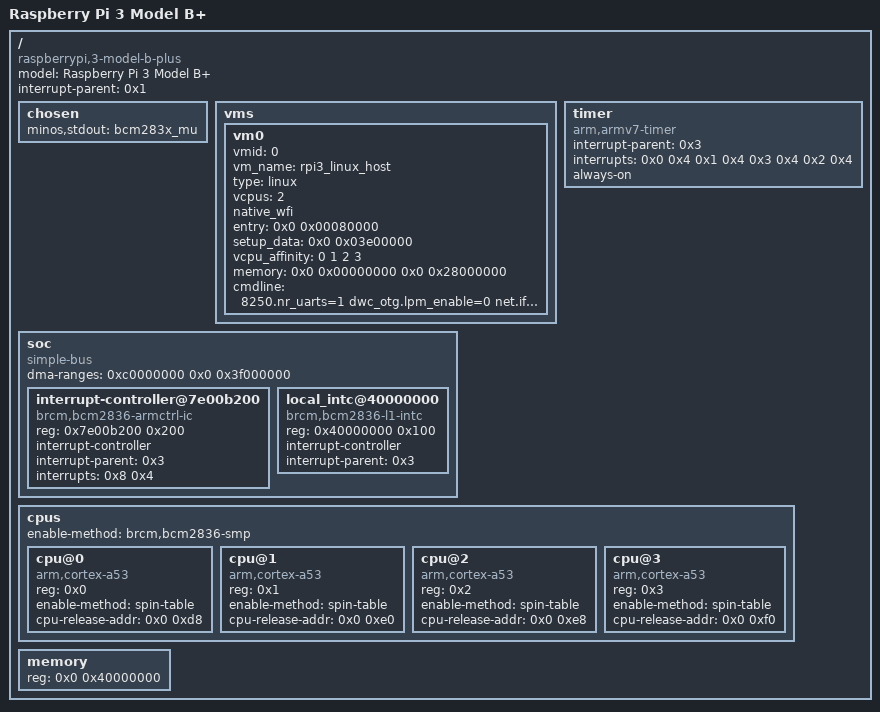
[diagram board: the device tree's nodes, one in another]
/dts-v1/;

/ {
	compatible = "raspberrypi,3-model-b-plus", "brcm,bcm2837";
	model = "Raspberry Pi 3 Model B+";
	interrupt-parent = <0x1>;
	#address-cells = <0x1>;
	#size-cells = <0x1>;

	chosen {
		minos,stdout = "bcm283x_mu";
	};

	vms {
		vm0 {
			device_type = "virtual_machine";
			vmid = <0>;
			vm_name = "rpi3_linux_host";
			type = "linux";
			vcpus = <2>;
			native_wfi;
			entry = <0x0 0x00080000>;
			setup_data = <0x0 0x03e00000>;
			vcpu_affinity = <0 1 2 3>;
			memory = <0x0 0x00000000 0x0 0x28000000>;
			cmdline = "8250.nr_uarts=1 dwc_otg.lpm_enable=0 net.ifnames=0 earlycon=uart8250,mmio32,0x3f215040 console=ttyS0,115200 cma=64M root=/dev/mmcblk0p2 rw rootfstype=ext4 elevator=deadline fsck.repair=yes rootwait noinitrd";
		};
	};

	soc {
		compatible = "simple-bus";
		#address-cells = <0x1>;
		#size-cells = <0x1>;
		ranges = <0x7e000000 0x3f000000 0x1000000 0x40000000 0x40000000 0x1000>;
		dma-ranges = <0xc0000000 0x0 0x3f000000>;

		interrupt-controller@7e00b200 {
			compatible = "brcm,bcm2836-armctrl-ic";
			reg = <0x7e00b200 0x200>;
			interrupt-controller;
			#interrupt-cells = <0x2>;
			interrupt-parent = <0x3>;
			interrupts = <0x8 0x4>;
			phandle = <0x1>;
		};

		local_intc@40000000 {
			compatible = "brcm,bcm2836-l1-intc";
			reg = <0x40000000 0x100>;
			interrupt-controller;
			#interrupt-cells = <0x2>;
			interrupt-parent = <0x3>;
			phandle = <0x3>;
		};

	};

	timer {
		compatible = "arm,armv7-timer";
		interrupt-parent = <0x3>;
		interrupts = <0x0 0x4 0x1 0x4 0x3 0x4 0x2 0x4>;
		always-on;
	};

	cpus {
		#address-cells = <0x1>;
		#size-cells = <0x0>;
		enable-method = "brcm,bcm2836-smp";

		cpu@0 {
			device_type = "cpu";
			compatible = "arm,cortex-a53";
			reg = <0x0>;
			enable-method = "spin-table";
			cpu-release-addr = <0x0 0xd8>;
		};

		cpu@1 {
			device_type = "cpu";
			compatible = "arm,cortex-a53";
			reg = <0x1>;
			enable-method = "spin-table";
			cpu-release-addr = <0x0 0xe0>;
		};

		cpu@2 {
			device_type = "cpu";
			compatible = "arm,cortex-a53";
			reg = <0x2>;
			enable-method = "spin-table";
			cpu-release-addr = <0x0 0xe8>;
		};

		cpu@3 {
			device_type = "cpu";
			compatible = "arm,cortex-a53";
			reg = <0x3>;
			enable-method = "spin-table";
			cpu-release-addr = <0x0 0xf0>;
		};
	};

	memory {
		device_type = "memory";
		reg = <0x0 0x40000000>;
	};
};
